# PIC32CZ2051CA90208 register map
Vendor: Microchip Technology; Series: PIC32CZCA90; File version: 0
CPU: CM7 r1p1, little endian, MPU, FPU, double-precision FPU, I-cache, D-cache, ITCM, DTCM, 3 interrupt priority bits, 222 interrupts
Registers are 32-bit, read-write, reset 0x0 unless marked. A register's access mark holds for its fields unless they carry their own. Offsets are from the block's base; [hi:lo] are bit positions; {n}, {i} and the like mark numbered series.

## SQI0 — Polaris Serial Quad Interface SIB
Base 0x4F008000; register names take the prefix SQI_
Same registers: SQI1 0x4F009000
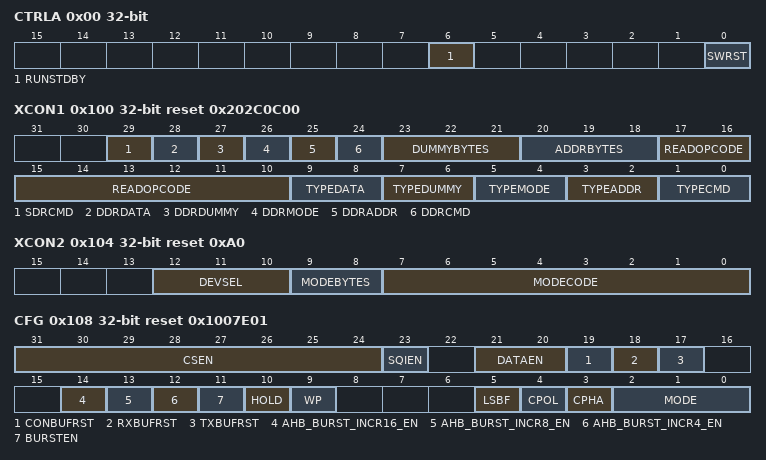
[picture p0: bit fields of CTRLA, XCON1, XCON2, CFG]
0x00 CTRLA write-1-sets — Control A register
  [6] RUNSTDBY — Run in Standby
    0=LOW (Module is disabled in Standby Sleep mode); 1=HIGH (Module continues to run in Standby Sleep mode)
  [0] SWRST — Software Reset
    0=LOW (No reset in progress); 1=HIGH (Reseting the registers and EIP)
0x10 INTENCLR — Interrupt Enable Clear Register
  [0] SQI — SQI Interrupt Enable Clear
    0=LOW (Interrupt Enabled); 1=HIGH (Interrupt Disabled)
0x14 INTENSET — Interrupt Enable Set Register
  [0] SQI — SQI Interrupt Enable Set
    0=LOW (Interrupt disabled); 1=HIGH (Interrupt enabled)
0x18 INTFLAG write-1-clears — Interrupt Status and Clear Register
  [0] SQI — Read value reflects the state of the interrupt flag. Do not use the interrupt flag and associated mask registers if the EIP already provides similar controls for its interrupts. This feature is design for interrupts created in the SIB or EIP which do not have mask or flag bits. Write to 1 to clear the flag.
0x20 SYNCBUSY ro
  [0] SWRST — Software Reset Synchronization Busy
    0=LOW (SWRST synchronization is not busy); 1=HIGH (SWRST synchronization is busy)
0x100 XCON1 reset 0x202C0C00 — SPI XIP Control1 register
  [29] SDRCMD — SPI TYPE CMD SDR2DDR: This bit is used by the controller only when XIP_SPI_TYPE_CMD_DDR is 1?b1 i.e., when command sent in DDR mode. 0 - The command (XIP_SPI_READ_OPCODE) will take 4 clock cycles. Data will go in both the edges. Used when Flash expecting the cmd in ddr mode. Here the command will go as 1byte only. 1- The command (XIP_SPI_READ_OPCODE) will take 8 clock cycles. Data will go in both the edges. Used when Flash expecting the cmd in sdr mode, but user wants to send in ddr mode. Here the command will go as 2bytes. The value (single byte) programmed in XIP_SPI_READ_OPCODE is replicated into 2bytes by the controller and sent on spi bus. Example for CMD SDR2DDR bit 1: Say opcode = 'h ac (1010 1100) Replicated pattern 11 00 11 00 11 11 00 00 ('h ccf0). So 1st 4 clock cycles hcc; next 4 clock cycles hf0 goes on spi bus.
  [28] DDRDATA — XIP SPI TYPE DATA DDR 0 - SDR mode, 1 - DDR mode. Based on this field, the boot controller will send the data in SDR/DDR mode.
  [27] DDRDUMMY — XIP SPI TYPE DUMMY DDR. 0 - SDR mode, 1 - DDR mode. Based on this field, the boot controller will send the dummy bytes in SDR/DDR mode.
  [26] DDRMODE — XIP SPI TYPE MODE DDR 0 - SDR mode, 1 - DDR mode. Based on this field, the boot controller will send the mode bytes in SDR/DDR mode.
  [25] DDRADDR — XIP SPI TYPE ADDR DDR 0 - SDR mode, 1 - DDR mode. Based on this field, the boot controller will send the address bytes in SDR/DDR mode.
  [24] DDRCMD — XIP SPI TYPE CMD DDR 0 - SDR mode, 1 - DDR mode. Based on this field, the boot controller will send the command in SDR/DDR mode.
  [23:21] DUMMYBYTES — 000 - Zero Dummy bytes ,001 - Transmit one dummy byte (8?h ff) ,010 - Transmit two dummy bytes (16?h ffff) ,011 - Transmit three dummy bytes (24?h ffffff) ,111 - Transmit Seven dummy bytes
  [20:18] ADDRBYTES — 000 - Zero Address Bytes ,001 - 1 Address Byte ,010 - 2 Address Bytes ,011 - 3 Address Bytes ,100 - 4 Address Bytes ,101 - 111- Reserved for Future Use
  [17:10] READOPCODE — 8bit opcode value for Read operation
  [9:8] TYPEDATA — SPI TYPE DATA: 00 - Single lane mode ,01 - Dual lane mode ,10 - Quad lane mode ,11 - Reserved for Future use Based on this field, the boot controller will receive the data in 1/2/4 lane.
  [7:6] TYPEDUMMY — SPI TYPE DUMMY: 00 - Single lane mode ,01 - Dual lane mode,10 - Quad lane mode ,11 - Reserved for Future use. Based on this field, the boot controller will send the Dummy in 1/2/4 lane.
  [5:4] TYPEMODE — SPI TYPE Mode: 00 - Single lane mode, 01 - Dual lane mode, 10 - Quad lane mode, 11 - Reserved for Future use. Based on this field, the boot controller will send the Mode in 1/2/4 lane.
  [3:2] TYPEADDR — SPI TYPE Address 00 - Single lane mode ,01 - Dual lane mode ,10 - Quad lane mode ,11 - Reserved for Future use Based on this field, the boot controller will send the Address in 1/2/4 lane.
  [1:0] TYPECMD — SPI TYPE Command - Single lane mode, - Dual lane mode, - Quad lane mode, - Reserved for Future use, Based on this field, the boot controller will send the command in 1/2/4 lane.
0x104 XCON2 reset 0xA0 — SPI XIP Control2 register
  [12:10] DEVSEL — XIP SPI Device Select: This field is used to select a particular SPI device 000 - Select Device0 , 001 - Select Device1 , 010 - Select Device2 , 011 - Select Device3 , 100 - Select Device4 , 101 - Select Device5 , 110 - Select Device6 , 111 - Select Device7
  [9:8] MODEBYTES — Mode Bytes 00 - 0 Mode Bytes , 01 - 1 Mode Byte , 10 - 2 Mode Bytes , 11 - 3 Mode Bytes
  [7:0] MODECODE — 8bit value for Mode byte
0x108 CFG reset 0x1007E01 — SPI Configuration Register
  [31:24] CSEN — 1 - Chip Select is used 0 - Chip Select is not used SPI_CS[7] for CS7, SPI_CS[6] for CS6, SPI_CS[5] for CS5, SPI_CS[4] for CS4, SPI_CS[3] for CS3, SPI_CS[2] for CS2, SPI_CS[1] for CS1, SPI_CS[0] for CS0. SPI_CS_PIN_EN[7:0/3:0] output pins are controlled by writing to these bits.
  [23] SQIEN — 1 - Enabled, 0 - Disabled SPI_ON output pin is controlled by writing to this bit.
  [21:20] DATAEN — Max Data Lanes 11 - Reserved, 10 - 4, 01 - 2, 00 - 1 SPI_OUT_PIN_EN[3:0] output pins are controlled by writing to these bits.
  [19] CONBUFRST — Control FIFO Reset A reset pulse is generated when writing 1 to this bit. This bit is Auto clear and SPI Controller will clear this bit. Control fifo pointers will get reset by this reset pulse. Note: Control FIFO reset can be done only after a transaction is complete on spi bus; however if we want to reset FIFO during transaction, we need to go for soft reset only. Note: For Michigan Ax versions, treat as Reserved, keep 0.
  [18] RXBUFRST — Receive FIFO Reset A reset pulse is generated when writing 1 to this bit. This bit is Auto clear and SPI Controller will clear this bit. Receive fifo pointers will get reset by this reset pulse. Note: Receive FIFO reset can be done only after a transaction is complete on spi bus; however if we want to reset FIFO during transaction, we need to go for soft reset only. Note: For Michigan Ax versions, treat as Reserved, keep 0.
  [17] TXBUFRST — Transmit FIFO Reset A reset pulse is generated when writing 1 to this bit. This bit is Auto clear and SPI Controller will clear this bit. Transmit FIFO pointers will get reset by this reset pulse. Note: Transmit FIFO reset can be done only after a transaction is complete on spi bus; however if we want to reset FIFO during transaction, we need to go for soft reset only.Note: For Michigan Ax versions, treat as Reserved, keep 0.
  [14] AHB_BURST_INCR16_EN — This field is used to configure the AHB Master Burst capability. 1 - AHB INCR16 is enabled. 0 - AHB INCR16 is disabled
  [13] AHB_BURST_INCR8_EN — This field is used to configure the AHB Master Burst capability. 1 - AHB INCR8 is enabled. 0 - AHB INCR8 is disabled
  [12] AHB_BURST_INCR4_EN — This field is used to configure the AHB Master Burst capability. 1 - AHB INCR4 is enabled. 0 - AHB INCR4 is disabled
  [11] BURSTEN — This field is used to configure the AHB Master Burst capability. 1 - AHB INCR is enabled 0 - AHB INCR is disabled
  [10] HOLD — Hold: In Single or Dual lane mode, this bit is used to drive the spiout3 signal. Whenever this bit is high, the controller drives 0 on spiout3 line and sets spimoe3 high (active only during transfer).
  [9] WP — Write Protect: In single or Dual lane mode, this bit is used to drive the spiout2 signal. Whenever this bit is high, the controller drives 0 on spiout2 line and sets spimoe2 high (active only during transfer).
  [5] LSBF — Data format on SPI interface 0 = MSBit sent/received first. 1 = LSBit sent/received first. This setting is supeceded by LSBF control bit in Buffer Descriptor during DMA operations.
  [4] CPOL — Clock polarity 0 = active-high SPICLK (SPICLK low is the idle state) 1 = active-low SPICLK (SPICLK high is the idle state)
  [3] CPHA — Clock phase (selects the transfer format) 0 = SPICLK starts toggling at the middle of 1st data bit. 1 = SPICLK starts toggling at the start of 1st data bit.
  [2:0] MODE — Mode Select The default value of this field is 0. After power on reset, the controller enters boot mode. 000 - Boot mode. The CSR registers are loaded with boot strap values. 001 - PIO mode. The controller is controlled by the CPU in PIO mode. 010 - DMA mode. 011 - XIP mode. When this mode is entered the controller behaves as if executing in Place (XIP) but uses the register data to control timing. 100 - 111 - Reserved
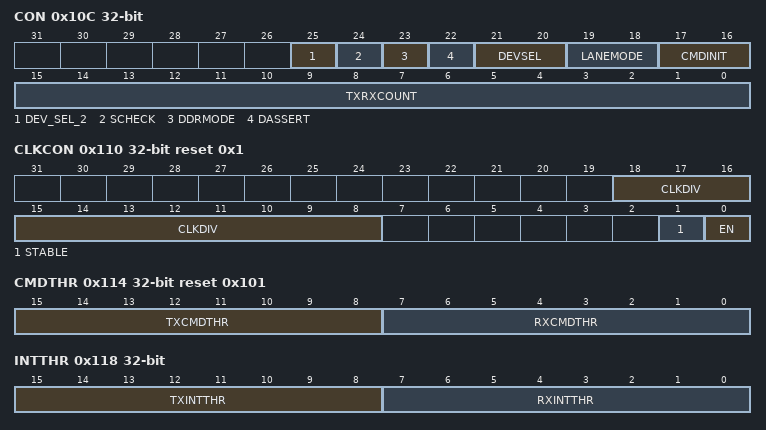
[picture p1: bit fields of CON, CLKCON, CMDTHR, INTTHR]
0x10C CON — SPI Control register
  [25] DEV_SEL_2 — SPI Device Select[2]: This field along with SPI DEVICE SELECT [1:0] (bits 21:20) together is used to select a particular SPI device. Bit25 Bit21 Bit20 0 0 0 - SPI Device 0 ,0 0 1 - SPI Device 1 ,0 1 0 - SPI Device 2 ,0 1 1 - SPI Device 3, 1 0 0 - SPI Device 4 ,1 0 1 - SPI Device 5 ,1 1 0 - SPI Device 6 ,1 1 1 - SPI Device 7 Note: For Michigan Ax versions, this bit is Reserved and should be kept 0.
  [24] SCHECK — Status Check This bit is mainly used for Programming or Erase operations. 0 - do not check status, 1 - check status. If this bit is set to 1, the hardware will issue the status command automatically after the current operation and wait for busy bit to clear. The hardware will issue the next command only after this Status check phase. Note: For Michigan Ax versions, this bit is Reserved and should be kept 0.
  [23] DDRMODE — SDR_DDR: 0 - SDR mode, 1 - DDR mode. Note: For Michigan Ax versions this bit is Reserved and should be kept 0.
  [22] DASSERT — Chip Select Assert 0 - CS is not de-asserted after transmission/reception of specified number of bytes in the control register 1 - CS is de-asserted after transmission/reception of specified number of bytes in the control register
  [21:20] DEVSEL — SPI Device Select: This field along with bit25 is used to select a particular SPI device. Note: For Michigan Ax versions, extension by bit25 is NOT used (only 4 devices are selectable, by bits 21:20 here).
  [19:18] LANEMODE — SPI Lane mode 00 - Single lane mode ,01 - Dual lane mode ,10 - Quad lane mode ,11 - Reserved for Future use
  [17:16] CMDINIT — This signal indicates the command initiation mode. If it is Transmit, Commands are initiated based on writes to transmit register or the contents of TX FIFO. If the CMD_INIT is Receive, commands are initiated based on reads to Read register or RX FIFO availability. 00 = Reserved. 01 = Initiate Transmit. 10 = Initiate Receive. 11 = Reserved. Note: If Boot mode is enabled, the default value is 2?b10 This is NOT active status field, see SPI Status2 Reg (0x30)
  [15:0] TXRXCOUNT — This bit specifies the total number of bytes to transmit or receive (based on CMD_INIT field). ,16?d 0 - Reserved,16?d 1 - 1byte to transmit/receive ,16?d 2 - 2bytes to transmit/receive NOTE: Count must be programmed to non-zero value prior to initiating transaction
0x110 CLKCON reset 0x1 — SPI Clock Control register
  [18:8] CLKDIV — SPI Clock Frequency Select 400h - base clock divided by 2048 ,200h - base clock divided by 1024 ,100h - base clock divided by 512 ,080h - base clock divided by 256 ,040h - base clock divided by 128 ,020h - base clock divided by 64 ,010h - base clock divided by 32 ,008h - base clock divided by 16 ,004h - base clock divided by 8 ,002h - base clock divided by 4 ,001h - base clock divided by 2 ,000h - base clock Setting 000h specifies the highest frequency of the SPI Clock. NOTE: When DDR mode is active, the output SPI_CLK is further divided by two (so that internal clocking remains rise edge active internally) Max output SPI_CLK for DDR is 66Mhz.
  [1] STABLE — After Reset, this bit is set to 1 when SPI Clock is stable after writing Internal Clock Enable in this register to 1. The Clock Stable indication will continue unless the Clock Divisor Value is changed, in which case it will wait until Clock is stable again. Stability is reached when the Clock Divisor period has been reached. The SPI Host Driver should wait until this bit is set to 1 (and the Enable is 1) before programming the SPI Control register. 1 - Stable 0 - Not stable
  [0] EN — This bit is set to 0 when the SPI Driver is not using the SPI Controller. The SPI Controller should stop its internal clock to go very low power state. Still, registers will be able to be read and written. Clock starts to oscillate when this bit is set to 1. When clock oscillation is stable, the SPI Controller will set Internal Clock Stable in this register to 1. 1 - Enable 0 - Disable
0x114 CMDTHR reset 0x101 — SPI command threshold register
  [15:8] TXCMDTHR — In TX Initiation Mode, SPI Performs a transmit Operation when TX_CMD_THRES bytes are present in the TX FIFO. This should usually be set to 1 for normal flash commands, and is desired to be set to a higher value for page programming. NOTE: Value of 8?d0 should be treated as Reserved (illegal) for this field. May produce unexpected activity on SPI bus. Furthermore, values should generally be limited to EVEN values (excepting a value of 1), and MUST be so limited in DMA mode.
  [7:0] RXCMDTHR — In RX initiation mode, SPI attempts to perform receive fetch operations until RX_CMD_THRES bytes of space remain in the receive buffer. If space for RX_CMD_THRES bytes is not present in the FIFO, then SPI would not initiate any transfer. RX_CMD_THRES should only be programmed when RX is not active, during IDLE or TX. Please note that if S/W performs any reads, thereby reducing the FIFO count, then HW would initiate RX transfer to get back FIFO count equal to RX_CMD_THRES. If S/W would not like any more words latched into FIFO, then command initiation mode needs to be changed to IDLE before any FIFO reads by S/W. In case of Boot/XIP mode, the SPI Controller uses the AHB Burst size, instead of RX CMD Threshold value.
0x118 INTTHR — SPI Interrupt Threshold register
  [15:8] TXINTTHR — Transmit Interrupt is set when Transmit FIFO has equal or more space than TX_INT_THRES bytes.
  [7:0] RXINTTHR — Receive Interrupt is set when Receive FIFO CNT is larger than or equal to RX_INT_THRES Value.
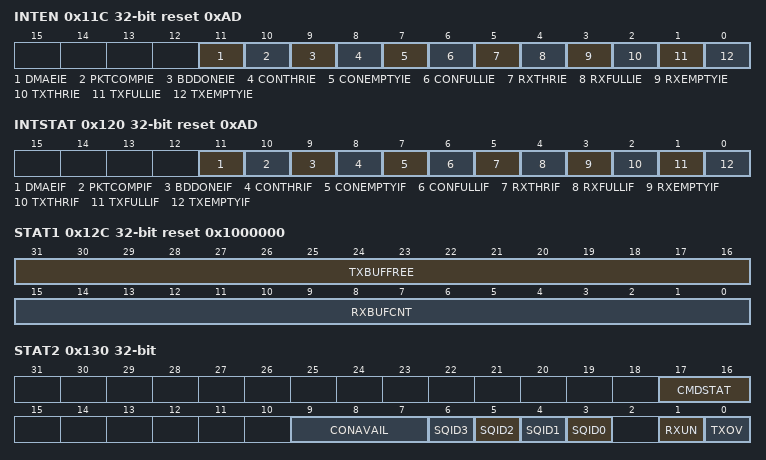
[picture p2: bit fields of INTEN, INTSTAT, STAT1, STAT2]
0x11C INTEN reset 0xAD — SPI Interrupt Enable Register
  [11] DMAEIE — Master Error Interrupt Enable
  [10] PKTCOMPIE — Packet completion Interrupt
  [9] BDDONEIE — Current Buffer Descriptor Interrupt Enable
  [8] CONTHRIE — Control Buffer Threshold Interrupt Enable
  [7] CONEMPTYIE — Control Buffer Empty Interrupt Enable
  [6] CONFULLIE — Control Buffer Full Interrupt Enable
  [5] RXTHRIE — Enable Interrupt to be generated when the RX FIFO has data more than or equal to RX_INT_THRES words. In case of Boot/XIP mode, the power on reset value of RX buffer threshold is zero. So this bit will be set to 1, immediately after power on reset, till a read request on the AHB Bus.
  [4] RXFULLIE — RX FIFO Full Interrupt Enable.
  [3] RXEMPTYIE — RX FIFO Empty Interrupt Enable.
  [2] TXTHRIE — Enable Interrupt to be generated when the TX FIFO has space equal to or more than TX_INT_THRES words.
  [1] TXFULLIE — TX FIFO Full Interrupt Enable.
  [0] TXEMPTYIE — TX FIFO Empty Interrupt Enable.
0x120 INTSTAT reset 0xAD — SPI Interrupt Status Register
  [11] DMAEIF — Master Error Interrupt
  [10] PKTCOMPIF — Packet completion Interrupt
  [9] BDDONEIF — BDP sets this bit to '1' after current buffer descriptor is processed
  [8] CONTHRIF — Control Buffer Threshold Interrupt
  [7] CONEMPTYIF — Control Buffer Empty Interrupt
  [6] CONFULLIF — Control Buffer Full Interrupt
  [5] RXTHRIF — Interrupt to be generated when the RX FIFO has data more than or equal to RX_INT_THRES words. In case of Boot/XIP mode, the power on reset value of RX buffer threshold is zero. So this bit will be set to 1, immediately after power on reset, till a read request on the AHB Bus.
  [4] RXFULLIF — RX FIFO Full Interrupt.
  [3] RXEMPTYIF — RX FIFO Empty Interrupt.
  [2] TXTHRIF — Interrupt to be generated when the TX FIFO has space equal to or more than TX_INT_THRES words.
  [1] TXFULLIF — TX FIFO Full Interrupt.
  [0] TXEMPTYIF — TX FIFO Empty Interrupt.
0x124 TXDATA read-modifies — SPI Transmit Data Register
  [31:0] TXDATA — Data is loaded into this register before being transmitted. Just prior to the beginning of a data transfer, the data in TX_DATA is loaded into the shift register. This register is used as a window to write data into Transmit buffer.
0x128 RXDATA ro write-1-clears read-modifies — SPI Receive Data Register
  [31:0] RXDATA — At the end of a data transfer, the data in the shift register is loaded into RX_DATA register. This register is used as a window to read data from Receive buffer.
0x12C STAT1 ro reset 0x1000000 — SPI Status1 Register
  [31:16] TXBUFFREE — Number of Words of Space available in the TX FIFO. Max value equals value of MEM_SIZE_BYTES parameter. Default value is Max
  [15:0] RXBUFCNT — Number of Words of Read Data in the FIFO.
0x130 STAT2 ro — SPI status 2 register
  [17:16] CMDSTAT — Reflect the (internal state machine) CMD_INIT value. Indicates whether the controller is in Transmit/Receive/IDLE state. 2?b00 - IDLE ,2?b01 - Transmit ,2?b10 - Receive ,2?b11 - Reserved
  [9:7] CONAVAIL — Indicates the number of entries in Control Buffer remaining. NOTE: This field not present in Michigan Ax versions. Treat as Reserved.
  [n+3] SQID{n} (n=0..3) — SPI Data bus: This status is used to check the SPI DATA line level for Debugging. Bit3 - SPI_IO0 ,Bit4 - SPI_IO1 ,Bit5 - SPI_IO2 ,Bit6 - SPI_IO3
  [1] RXUN — This bit would get set when RX FIFO UNDERFLOW happens. S/W needs to monitor RX_FIFO_CNT when emptying RX_FIFO to make sure RX FIFO doesn?t under flow or in case UNDERFLOW bit gets set, then RX_FIFO_RST (bit 18 of SPI Configuration register) must be set which would then clear RX FIFO pointers and hence this bit would get cleared. Generally software should avoid getting into this condition.
  [0] TXOV — This bit would get set when TX FIFO OVERFLOW happens. S/W needs to monitor TX_FIFO_FREE when filling TX_FIFO to make sure TX FIFO doesn?t over flow or in case OVERFLOW bit gets set, then TX_FIFO_RST (bit 17 of SPI Configuration register) should be set which would then clear TX FIFO pointers and hence this bit would get cleared. Generally software should avoid getting into this condition.
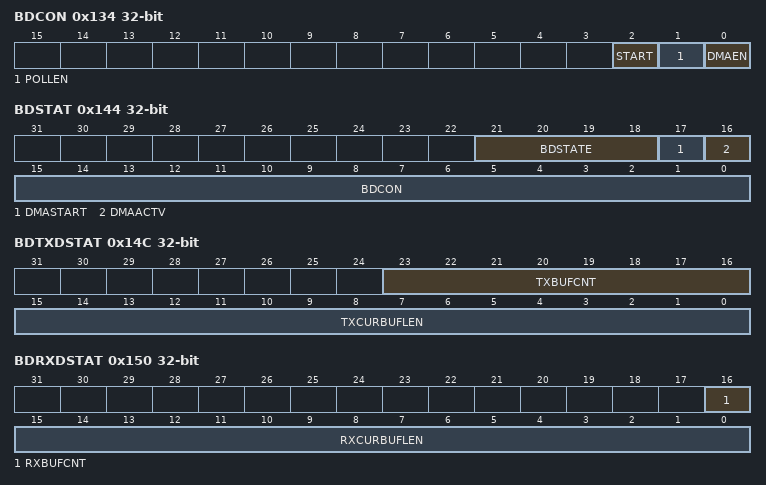
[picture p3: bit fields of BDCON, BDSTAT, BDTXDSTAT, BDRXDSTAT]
0x134 BDCON — BD_CTRL Register
  [2] START — Setting this bit to '1' would start BDP (Buffer Descriptor Processor) to fetch a descriptor and hence this bit should be enabled only after all the DMA descriptor programming is done. Hardware clears this bit automatically after one clock cycle.
  [1] POLLEN — Setting this bit would cause Buffer Descriptor processor (BDP) to poll for descriptor valid till descriptor valid bit is set or till poll counter expires based on value programmed in BD_POLL_CTRL register.
  [0] DMAEN — DMA Enable Bit 1 - Enabled, 0 - Disabled
0x138 BDCURADD ro — BD_CURR_ADDR Register
  [31:0] BDCURRADDR — This register field contains the current descriptor address being processed by Buffer Descriptor Processor (BDP)
0x140 BDBASEADD — BD_BASE_ADDR register
  [31:0] BDADDR — This register field contains the base address of the DMA. This register must be updated only when the DMA is IDLE.
0x144 BDSTAT ro — BD_STATUS Register
  [21:18] BDSTATE — This register field contains current BDP state : 0 IDLE, 1 Descriptor fetch Request Pending, 2 BD loading, 3 Data phase , 4 Descriptor Done, 5 Fetched BD is disabled, 6 Wait for Control Buffer Available, 7 Wait for AHB Error Acknowledgement
  [17] DMASTART — This register field would indicate whether DMA has started or not, if bit it set '1', then it indicates DMA start has happened. Value of '0' would indicate that DMA hasn't started.
  [16] DMAACTV — A value of '1' would indicate that Buffer Descriptor Processor (BDP) is not Idle. Value of '0' would indicate that BDP is in IDLE state
  [15:0] BDCON — This register field contains the current Descriptor control information. Bits [31:16] of BD_CTRL field of current descriptor are indicated in this register field.
0x148 BDPOLLCON — BD_POLL_CTRL Register
  [15:0] POLLCON — Number of cycles that BDP block would wait before re-fetching the Descriptor control word if the previous descriptor fetched was disabled
0x14C BDTXDSTAT — BD_TX_DMA_STATUS Register
  [23:16] TXBUFCNT — This register field gives the information about the internal transmit FIFO space.
  [15:0] TXCURBUFLEN — This register field gives the length of the current buffer transmit length
0x150 BDRXDSTAT ro — BD_RX_DMA_STATUS Register
  [16] RXBUFCNT — This register field gives the information about the internal receive FIFO space.
  [15:0] RXCURBUFLEN — This register field gives the length of the current buffer receive length
0x154 THR — SPI Control threshold register
  [2:0] THRES — SPI Control Threshold Value. SPI Control Threshold Interrupt is asserted, whenever larger than SPI Control Threshold amount of space available in SPI Control Buffer.
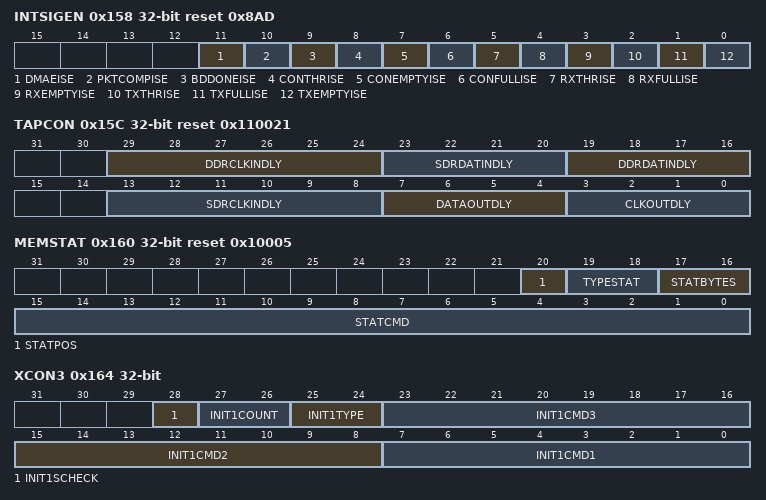
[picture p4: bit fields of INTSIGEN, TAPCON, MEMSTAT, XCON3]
0x158 INTSIGEN reset 0x8AD — SPI Interrupt Signal Enable Register
  [11] DMAEISE — Master Error Interrupt Signal Enable
  [10] PKTCOMPISE — Packet completion Interrupt Signal Enable
  [9] BDDONEISE — Current Buffer Descriptor Interrupt Signal Enable
  [8] CONTHRISE — Control Buffer Threshold Interrupt Signal Enable
  [7] CONEMPTYISE — Control Buffer Empty Interrupt Signal Enable
  [6] CONFULLISE — Control Buffer Full Interrupt Signal Enable
  [5] RXTHRISE — Signal Enable Interrupt to be generated when the RX FIFO has data more than or equal to RX_INT_THRES words. In case of Boot/XIP mode, the power on reset value of RX buffer threshold is zero. So this bit will be set to 1, immediately after power on reset, till a read request on the AHB Bus.
  [4] RXFULLISE — RX FIFO Full Interrupt Signal Enable.
  [3] RXEMPTYISE — RX FIFO Empty Interrupt Signal Enable.
  [2] TXTHRISE — Signal Enable Interrupt to be generated when the TX FIFO has space equal to or more than TX_INT_THRES words.
  [1] TXFULLISE — TX FIFO Full Interrupt Signal Enable.
  [0] TXEMPTYISE — TX FIFO Empty Interrupt Signal Enable.
0x15C TAPCON reset 0x110021 — Tap Control Register
  [29:24] DDRCLKINDLY — Used only in DDR mode. This field is used to add tap delay cells on the spi clock input. Based on the mode of operation (SDR Vs DDR), the controller dynamically picks the appropriate delay values (CLK_IN_DLY_CNT Vs CLK_IN_ALT_DLY_CNT).
  [23:20] SDRDATINDLY — Used only in SDR mode. This field is used to add tap delay cells on the Data input. Based on the mode of operation (SDR Vs DDR), the controller dynamically picks the appropriate delay values (DATA_IN_ALT_DLY_CNT Vs DATA_IN_DLY_CNT).
  [19:16] DDRDATINDLY — Used only in DDR mode. This field is used to add tap delay cells on the data input. Based on the mode of operation (SDR Vs DDR), the controller dynamically picks the appropriate delay values (DATA_IN_ALT_DLY_CNT Vs DATA_IN_DLY_CNT).
  [13:8] SDRCLKINDLY — Used only in SDR mode. This field is used to add tap delay cells on the spi clock input. Based on the mode of operation (SDR Vs DDR), the controller dynamically picks the appropriate delay values (CLK_IN_DLY_CNT Vs CLK_IN_ALT_DLY_CNT).
  [7:4] DATAOUTDLY — Used to add delay on spi data outputs (1/2/4lanes). 16 taps available.
  [3:0] CLKOUTDLY — Used to add delay on spi clock output.16 taps available.
0x160 MEMSTAT reset 0x10005 — SPI Status Control Register
  [20] STATPOS — Indicates whether the BUSY bit position in Status Register of flash is 0 or 7. 1?b0 - 0th bit position (bit 0 is valid for busy status), 1?b1 - 7th bit position (bit7 is valid for busy status) The Controller continuously reads the Status register value from flash until this bit which indicates the flash busy status goes low.
  [19:18] TYPESTAT — Status Lane: Indicates the number of lanes (single/dual/quad) in which the Status command/ Read Status Register value is transmitted to /received from flash. 2?b00 - single lane, 2?b01 - dual lane, 2?b10 - quad lane
  [17:16] STATBYTES — No. of bytes to send: 00 - Reserved ,01 - 1 byte ,10 - 2 bytes ,11 - Reserved
  [15:0] STATCMD — Status Data: The first byte to be sent must be in LSB. For example if the user wants to send 0F first and 0C second, then we should program 16?h0C0F.
0x164 XCON3 — SPI XIP Control 3 Register
  [28] INIT1SCHECK — SPI Init1 Status Check: 0 - do not check status, 1 - check status. If this bit is set to 1, the hardware will issue the status command automatically after the current operation and wait for busy bit to clear. The hardware will issue the next command only after this Status check phase. Note: The Status Command will be formed according to the settings in the SPI Status Control Reg (@0x60)
  [27:26] INIT1COUNT — 2bit SPI INIT1 Count. Indicates whether 1, 2 or 3 bytes of INIT1 Code value are being sent.
  [25:24] INIT1TYPE — SPI TYPE INIT1: 00 - Single lane mode , 01 - Dual lane mode , 10 - Quad lane mode , 11 - Reserved for Future use. Based on this field, the boot controller will send the INIT1 Code in 1/2/4 lane.
  [23:16] INIT1CMD3 — 8bit SPI Init1 Code3 value.
  [15:8] INIT1CMD2 — 8bit SPI Init1 Code2 value.
  [7:0] INIT1CMD1 — 8bit SPI Init1 Code1 value.
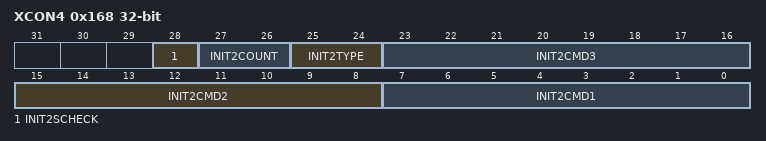
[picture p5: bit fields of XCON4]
0x168 XCON4 — SPI XIP Control4 Register
  [28] INIT2SCHECK — SPI Init2 Status Check: 0 - do not check status 1 - check status If this bit is set to 1, the hardware will issue the status command automatically after thecurrent operation and wait for busy bit to clear. The hardware will issue the next command only after this Status check phase. Note: The Status Command will be formed according to the settings in the SPI Status Control Reg (@0x60)
  [27:26] INIT2COUNT — 2bit SPI INIT2 Count. Indicates whether 1, 2 or 3 bytes of INIT2 Code value are being sent.
  [25:24] INIT2TYPE — SPI TYPE INIT2: 00 - Single lane mode. 01 - Dual lane mode. 10 - Quad lane mode. 11 - Reserved for Future use. Based on this field, the boot controller will send the INIT2 Code in 1/2/4 lane.
  [23:16] INIT2CMD3 — 8bit SPI Init2 Code3 value
  [15:8] INIT2CMD2 — 8bit SPI Init2 Code2 value
  [7:0] INIT2CMD1 — 8bit SPI Init2 Code1 value.
